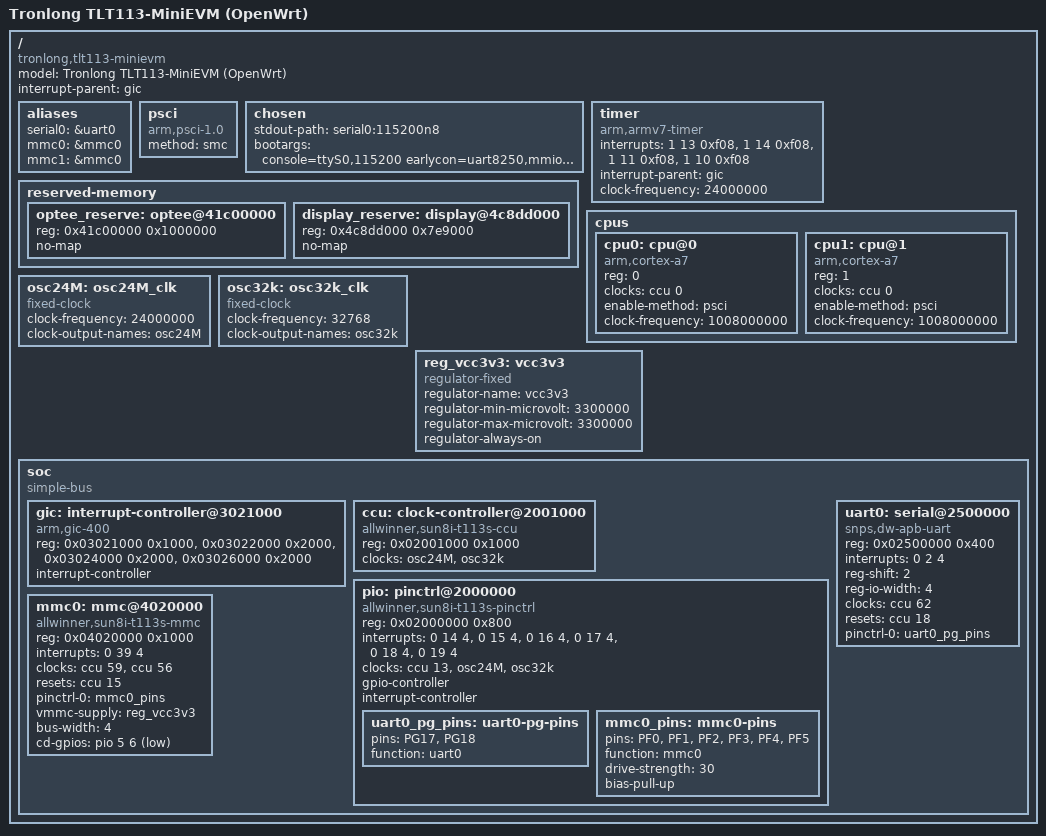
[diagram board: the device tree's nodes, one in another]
/dts-v1/;

/ {
    model = "Tronlong TLT113-MiniEVM (OpenWrt)";
    compatible = "tronlong,tlt113-minievm", "allwinner,sun8i-t113s", "allwinner,sun8i";

    #address-cells = <1>;
    #size-cells = <1>;

    interrupt-parent = <&gic>;

    /* 别名映射：解决官方 U-Boot 强传 mmcblk1p5 的路径问题 */
    aliases {
        serial0 = &uart0;
        mmc0 = &mmc0;
        mmc1 = &mmc0; /* 这里的 mmc1 别名指向物理 mmc0 节点 */
    };

    /* 多核启动支持 */
    psci {
        compatible = "arm,psci-1.0", "arm,psci-0.2";
        method = "smc";
    };

    chosen {
        stdout-path = "serial0:115200n8";
        /* 虽然加了别名，我们依然在 bootargs 里写 mmcblk1p5 以匹配 U-Boot 环境变量 */
        bootargs = "console=ttyS0,115200 earlycon=uart8250,mmio32,0x02500000 root=/dev/mmcblk1p5 rootwait panic=10 clk_ignore_unused initcall_debug=1";
    };

    timer {
        compatible = "arm,armv7-timer";
        interrupts = <1 13 0xf08>,
                     <1 14 0xf08>,
                     <1 11 0xf08>,
                     <1 10 0xf08>;
        interrupt-parent = <&gic>;
        clock-frequency = <24000000>;
    };

    reserved-memory {
        #address-cells = <1>;
        #size-cells = <1>;
        ranges;

        optee_reserve: optee@41c00000 {
            reg = <0x41c00000 0x1000000>;
            no-map;
        };

        display_reserve: display@4c8dd000 {
            reg = <0x4c8dd000 0x7e9000>;
            no-map;
        };
    };

    cpus {
        #address-cells = <1>;
        #size-cells = <0>;

        cpu0: cpu@0 {
            compatible = "arm,cortex-a7";
            device_type = "cpu";
            reg = <0>;
            clocks = <&ccu 0>;
            enable-method = "psci";
            clock-frequency = <1008000000>;
        };

        cpu1: cpu@1 {
            compatible = "arm,cortex-a7";
            device_type = "cpu";
            reg = <1>;
            clocks = <&ccu 0>;
            enable-method = "psci";
            clock-frequency = <1008000000>;
        };
    };

    osc24M: osc24M_clk {
        #clock-cells = <0>;
        compatible = "fixed-clock";
        clock-frequency = <24000000>;
        clock-output-names = "osc24M";
    };

    osc32k: osc32k_clk {
        #clock-cells = <0>;
        compatible = "fixed-clock";
        clock-frequency = <32768>;
        clock-output-names = "osc32k";
    };

    reg_vcc3v3: vcc3v3 {
        compatible = "regulator-fixed";
        regulator-name = "vcc3v3";
        regulator-min-microvolt = <3300000>;
        regulator-max-microvolt = <3300000>;
        regulator-always-on;
    };

    soc {
        compatible = "simple-bus";
        #address-cells = <1>;
        #size-cells = <1>;
        ranges;

        gic: interrupt-controller@3021000 {
            compatible = "arm,gic-400";
            reg = <0x03021000 0x1000>,
                  <0x03022000 0x2000>,
                  <0x03024000 0x2000>,
                  <0x03026000 0x2000>;
            interrupt-controller;
            #interrupt-cells = <3>;
            device_type = "interrupt-controller";
        };

        ccu: clock-controller@2001000 {
            compatible = "allwinner,sun8i-t113s-ccu", "allwinner,sun20i-d1-ccu";
            reg = <0x02001000 0x1000>;
            clocks = <&osc24M>, <&osc32k>;
            clock-names = "hosc", "losc";
            #clock-cells = <1>;
            #reset-cells = <1>;
        };

        pio: pinctrl@2000000 {
            compatible = "allwinner,sun8i-t113s-pinctrl", "allwinner,sun20i-d1-pinctrl";
            reg = <0x02000000 0x800>;
            /* 核心修正：补全全部 6 个中断 (Index 0-5) 对应 Bank B-G */
            /* 解决了 IRQ index 3 not found 报错 */
            interrupts = <0 14 4>, <0 15 4>, <0 16 4>, <0 17 4>, <0 18 4>, <0 19 4>;
            clocks = <&ccu 13>, <&osc24M>, <&osc32k>;
            clock-names = "apb", "hosc", "losc";
            gpio-controller;
            #gpio-cells = <3>;
            interrupt-controller;
            #interrupt-cells = <3>;

            uart0_pg_pins: uart0-pg-pins {
                pins = "PG17", "PG18";
                function = "uart0";
            };

            mmc0_pins: mmc0-pins {
                pins = "PF0", "PF1", "PF2", "PF3", "PF4", "PF5";
                function = "mmc0";
                drive-strength = <30>;
                bias-pull-up;
            };
        };

        uart0: serial@2500000 {
            compatible = "snps,dw-apb-uart";
            reg = <0x02500000 0x400>;
            interrupts = <0 2 4>;
            reg-shift = <2>;
            reg-io-width = <4>;
            clocks = <&ccu 62>;
            resets = <&ccu 18>;
            status = "okay";
            pinctrl-names = "default";
            pinctrl-0 = <&uart0_pg_pins>;
        };

        mmc0: mmc@4020000 {
            compatible = "allwinner,sun8i-t113s-mmc", "allwinner,sun20i-d1-mmc";
            reg = <0x04020000 0x1000>;
            interrupts = <0 39 4>;
            clocks = <&ccu 59>, <&ccu 56>;
            clock-names = "ahb", "mmc";
            resets = <&ccu 15>;
            reset-names = "ahb";
            pinctrl-names = "default";
            pinctrl-0 = <&mmc0_pins>;
            vmmc-supply = <&reg_vcc3v3>;
            bus-width = <4>;
            cd-gpios = <&pio 5 6 1>;
            status = "okay";
        };
    };
};
